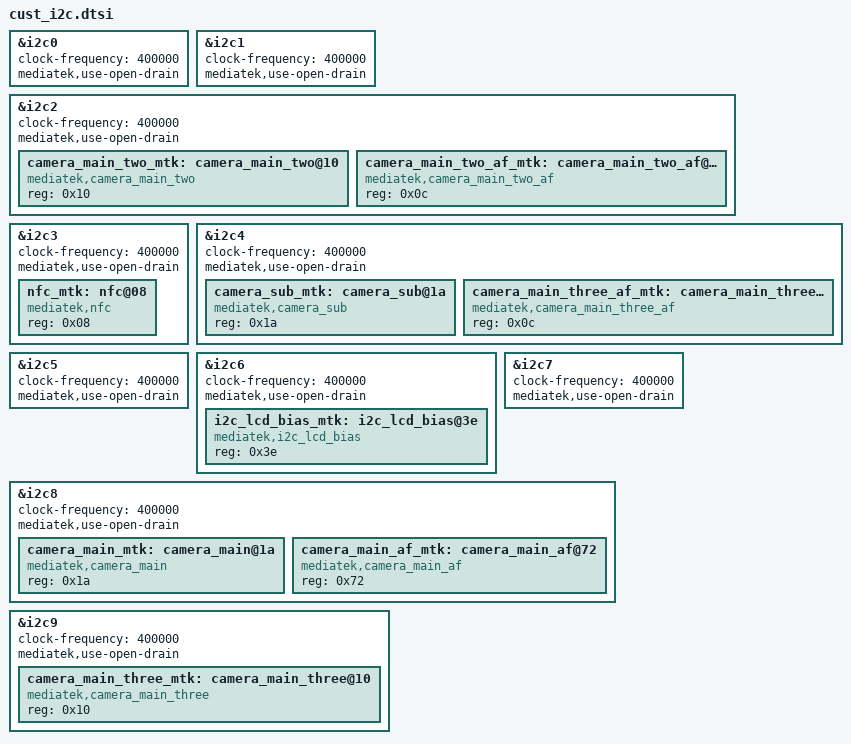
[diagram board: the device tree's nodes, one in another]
/*
 * Generated by MTK SP DrvGen Version: 3.5.160809 for MT6853.
 * 2023-03-11 17:22:09
 * Do Not Modify The File.
 * Copyright Mediatek Inc. (c) 2016.
*/

/*************************
 * I2C DTSI File
*************************/

&i2c0 {
	#address-cells = <1>;
	#size-cells = <0>;
	clock-frequency = <400000>;
	mediatek,use-open-drain;
};

&i2c1 {
	#address-cells = <1>;
	#size-cells = <0>;
	clock-frequency = <400000>;
	mediatek,use-open-drain;
};

&i2c2 {
	#address-cells = <1>;
	#size-cells = <0>;
	clock-frequency = <400000>;
	mediatek,use-open-drain;
	camera_main_two_mtk:camera_main_two@10 {
		compatible = "mediatek,camera_main_two";
		reg = <0x10>;
		status = "okay";
	};

	camera_main_two_af_mtk:camera_main_two_af@0c {
		compatible = "mediatek,camera_main_two_af";
		reg = <0x0c>;
		status = "okay";
	};

};

&i2c3 {
	#address-cells = <1>;
	#size-cells = <0>;
	clock-frequency = <400000>;
	mediatek,use-open-drain;
	nfc_mtk:nfc@08 {
		compatible = "mediatek,nfc";
		reg = <0x08>;
		status = "okay";
	};

};

&i2c4 {
	#address-cells = <1>;
	#size-cells = <0>;
	clock-frequency = <400000>;
	mediatek,use-open-drain;
	camera_sub_mtk:camera_sub@1a {
		compatible = "mediatek,camera_sub";
		reg = <0x1a>;
		status = "okay";
	};

	camera_main_three_af_mtk:camera_main_three_af@0c {
		compatible = "mediatek,camera_main_three_af";
		reg = <0x0c>;
		status = "okay";
	};

};

&i2c5 {
	#address-cells = <1>;
	#size-cells = <0>;
	clock-frequency = <400000>;
	mediatek,use-open-drain;
};

&i2c6 {
	#address-cells = <1>;
	#size-cells = <0>;
	clock-frequency = <400000>;
	mediatek,use-open-drain;
	i2c_lcd_bias_mtk:i2c_lcd_bias@3e {
		compatible = "mediatek,i2c_lcd_bias";
		reg = <0x3e>;
		status = "okay";
	};

};

&i2c7 {
	#address-cells = <1>;
	#size-cells = <0>;
	clock-frequency = <400000>;
	mediatek,use-open-drain;
};

&i2c8 {
	#address-cells = <1>;
	#size-cells = <0>;
	clock-frequency = <400000>;
	mediatek,use-open-drain;
	camera_main_mtk:camera_main@1a {
		compatible = "mediatek,camera_main";
		reg = <0x1a>;
		status = "okay";
	};

	camera_main_af_mtk:camera_main_af@72 {
		compatible = "mediatek,camera_main_af";
		reg = <0x72>;
		status = "okay";
	};

};

&i2c9 {
	#address-cells = <1>;
	#size-cells = <0>;
	clock-frequency = <400000>;
	mediatek,use-open-drain;
	camera_main_three_mtk:camera_main_three@10 {
		compatible = "mediatek,camera_main_three";
		reg = <0x10>;
		status = "okay";
	};

};

